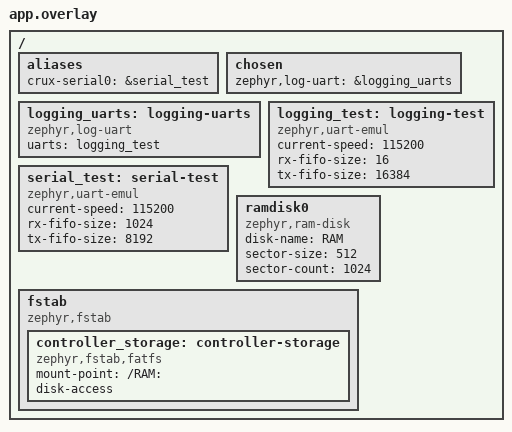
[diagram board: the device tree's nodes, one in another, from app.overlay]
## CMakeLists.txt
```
# SPDX-License-Identifier: Apache-2.0

# The held-application scenario of the controller framework on native_sim: the fixture application
# of ../fixture in the production watchdog configuration with no watchdog (criterion 19). This file
# names no source or include directory of the framework.

cmake_minimum_required(VERSION 3.20.0)
find_package(Zephyr REQUIRED HINTS $ENV{ZEPHYR_BASE})
project(controller_framework_application_held_native_sim LANGUAGES C)

if(NOT CONFIG_BOARD_NATIVE_SIM OR NOT CONFIG_FAKE_ENTROPY_NATIVE_SIM)
    message(FATAL_ERROR "This scenario is restricted to native_sim: its entropy source is a test source")
endif()
if(NOT CONFIG_CRUX_CONTROLLER_FRAMEWORK_SUPERVISION OR NOT CONFIG_CRUX_CONTROLLER_FRAMEWORK_MANAGEMENT
   OR CONFIG_CRUX_CONTROLLER_START_WITHOUT_WATCHDOG OR CONFIG_CRUX_CONTROLLER_FRAMEWORK_FAULT_INJECTION
   OR CONFIG_CRUX_SYSTEM_NATIVE_SIM_WATCHDOG OR CONFIG_TASK_WDT_HW_FALLBACK)
    message(FATAL_ERROR "The held-application scenario needs the production watchdog configuration "
                        "with no watchdog")
endif()

target_sources(app PRIVATE src/test_application_held.c ../fixture/fixture.c ../common/scenario.c)
target_include_directories(app PRIVATE ../common ../fixture)
target_link_libraries(app PRIVATE controller::framework crux::file crux::configuration crux::logging)
controller_framework_image()
```

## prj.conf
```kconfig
# The held-application scenario of the controller framework on native_sim (criterion 19, application
# part, delivery stage 3): the configuration of the base scenario (tests/framework/base/prj.conf), in
# its production watchdog configuration (no task watchdog hardware fallback, no start without a
# watchdog, no fault injection) with no watchdog behind the alias crux-watchdog0, and the fixture
# application of ../fixture. The watchdog is not armed, so the controller is degraded and the
# application is held (decision D14). The program of src/test_application_held.c prints what Twister's console harness
# matches (testcase.yaml); it uses no ztest.
CONFIG_CRUX_CONTROLLER_FRAMEWORK=y
CONFIG_SNTP=y
CONFIG_CRUX_CONTROLLER_TIME_SERVER="127.0.0.1"

# Health supervision as in the base image (app/conf/base.conf), in its production watchdog
# configuration (criterion 19): no task watchdog hardware fallback, no start without a watchdog, no
# fault injection. native_sim has no watchdog behind the alias crux-watchdog0 here, so the watchdog
# is not armed and the controller is degraded. There is no retained region either, so the boot
# counter lives in RAM. The stable period is longer than the scenario, so the counter is not cleared.
CONFIG_TASK_WDT=y
CONFIG_TASK_WDT_HW_FALLBACK=n
CONFIG_CRUX_REBOOT=y
CONFIG_CRUX_CONTROLLER_STABLE_PERIOD_S=3600

CONFIG_CRUX_SERIAL=y
CONFIG_CRUX_CLI=y
CONFIG_CRUX_CLI_CONSOLE=y
CONFIG_CRUX_CLI_CONSOLE_PRIORITY=11
CONFIG_UART_INTERRUPT_DRIVEN=y
CONFIG_UART_USE_RUNTIME_CONFIGURE=y

CONFIG_STD_C17=y
CONFIG_EMUL=y
CONFIG_UART_EMUL=y
CONFIG_IRQ_OFFLOAD=y
# The web adapter refuses the external libc of native_sim; the management scenario runs on picolibc.
CONFIG_PICOLIBC=y
# One thread of the test runs the start sequence (key generation, signing, the format of the RAM
# disk) and the TLS client. Not measured.
CONFIG_MAIN_STACK_SIZE=32768
CONFIG_HEAP_MEM_POOL_SIZE=32768

# The Mbed TLS profile of app/conf/management.conf, as a copy: this scenario has no Kconfig of the product,
# as in the management scenario. The heap is larger than the product's 120,000 bytes,
# because the TLS client of the test runs in the same process and takes up to one more connection
# and its own handshake. The product declares 120,000 bytes for three server connections of 34,912
# bytes, a handshake of 3,576 bytes and the other PSA users, and 180,000 leaves about 25,000 bytes
# over the worst concurrent case that this process can reach. A paper figure, not measured.
CONFIG_MBEDTLS=y
CONFIG_MBEDTLS_PSA_CRYPTO_C=y
CONFIG_PSA_CRYPTO_PROVIDER_MBEDTLS=y
CONFIG_MBEDTLS_ENABLE_HEAP=y
CONFIG_MBEDTLS_HEAP_SIZE=180000
CONFIG_MBEDTLS_SSL_IN_CONTENT_LEN=16384
CONFIG_MBEDTLS_SSL_OUT_CONTENT_LEN=16384
CONFIG_MBEDTLS_SSL_PROTO_TLS1_2=y
CONFIG_MBEDTLS_SSL_PROTO_TLS1_3=y
CONFIG_MBEDTLS_SSL_TLS1_3_KEY_EXCHANGE_MODE_EPHEMERAL_ENABLED=y
CONFIG_MBEDTLS_KEY_EXCHANGE_ECDHE_ECDSA_ENABLED=y
CONFIG_MBEDTLS_CIPHERSUITE_TLS_ECDHE_ECDSA_WITH_AES_128_GCM_SHA256=y
CONFIG_MBEDTLS_CIPHERSUITE_TLS1_3_AES_128_GCM_SHA256=y
CONFIG_PSA_WANT_ALG_SHA_256=y
CONFIG_PSA_WANT_ECC_SECP_R1_256=y
CONFIG_PSA_WANT_ALG_ECDSA=y
CONFIG_PSA_WANT_ALG_ECDH=y
CONFIG_PSA_WANT_ALG_GCM=y
CONFIG_PSA_WANT_KEY_TYPE_AES=y
CONFIG_PSA_WANT_ALG_HMAC=y
CONFIG_PSA_WANT_KEY_TYPE_HMAC=y
CONFIG_PSA_WANT_ALG_HKDF=y
CONFIG_PSA_WANT_ALG_PBKDF2_HMAC=y
CONFIG_PSA_WANT_ALG_TLS12_PRF=y
CONFIG_PSA_WANT_KEY_TYPE_ECC_PUBLIC_KEY=y
CONFIG_PSA_WANT_KEY_TYPE_ECC_KEY_PAIR_IMPORT=y
CONFIG_PSA_WANT_KEY_TYPE_ECC_KEY_PAIR_EXPORT=y
CONFIG_PSA_WANT_KEY_TYPE_ECC_KEY_PAIR_GENERATE=y
CONFIG_PSA_WANT_KEY_TYPE_ECC_KEY_PAIR_DERIVE=y
CONFIG_MBEDTLS_PK_WRITE_C=y
CONFIG_CRUX_PSA_THREADING=y

# The Crux services, as in app/conf/management.conf. The module selects Thread, Sync and Time for them.
CONFIG_CRUX_ACCESS=y
CONFIG_CRUX_CONFIG_SERVICE=y
CONFIG_CRUX_MGMT_STATUS=y
CONFIG_CRUX_TLS_CERTIFICATE=y
CONFIG_CRUX_WEB=y
CONFIG_CRUX_WEB_SESSION=y
CONFIG_CRUX_WEB_MANAGEMENT=y
CONFIG_CRUX_SYSTEM=y
CONFIG_CRUX_NETIF=y
CONFIG_WATCHDOG=y
CONFIG_HWINFO=y
CONFIG_REBOOT=y

# The listener binds the loopback address, and the TLS client of the test is in the same process. The
# listener opens on Zephyr's own thread, so the client retries its connect.
CONFIG_CRUX_WEB_PORT=443
CONFIG_CRUX_WEB_BIND_ADDRESS="127.0.0.1"
CONFIG_CRUX_WEB_BACKLOG=4
CONFIG_HTTP_SERVER_MAX_CLIENTS=3
CONFIG_HTTP_SERVER_STACK_SIZE=16384
CONFIG_CRUX_WEB_SESSION_WORKER_PRIORITY=11
CONFIG_CRUX_WEB_MANAGEMENT_WORKER_PRIORITY=11
CONFIG_CRUX_SECURITY_EVENT_DRAIN_PRIORITY=11

# The simulator's fake entropy source: test-only, so nothing made here is a secret.
CONFIG_ENTROPY_GENERATOR=y

# Crux File on a RAM disk with the simulator provider, and the formatting service that the zone
# uses when the blank disk does not mount.
CONFIG_FILE_SYSTEM=y
CONFIG_FILE_SYSTEM_MKFS=y
CONFIG_FAT_FILESYSTEM_ELM=y
CONFIG_FS_FATFS_LFN=y
CONFIG_FS_FATFS_LFN_MODE_STACK=y
CONFIG_FS_FATFS_MAX_LFN=127
CONFIG_FS_FATFS_MOUNT_MKFS=n
CONFIG_FS_FATFS_REENTRANT=y
CONFIG_FS_FATFS_NUM_FILES=6
CONFIG_DISK_DRIVERS=y
CONFIG_DISK_DRIVER_RAM=y
CONFIG_CRUX_FILE_FATFS_SIMULATOR=y

# The network: Zephyr's loopback interface, TCP and the TLS socket layer, with no host network.
CONFIG_NETWORKING=y
CONFIG_NET_IPV4=y
CONFIG_NET_IPV6=n
CONFIG_NET_TCP=y
CONFIG_NET_UDP=y
CONFIG_NET_SOCKETS=y
CONFIG_NET_DRIVERS=y
CONFIG_NET_LOOPBACK=y
CONFIG_NET_SOCKETS_SOCKOPT_TLS=y
CONFIG_TLS_CREDENTIALS=y
CONFIG_TLS_MAX_CREDENTIALS_NUMBER=4
CONFIG_NET_SOCKETS_TLS_MAX_CONTEXTS=6
CONFIG_ZVFS_OPEN_MAX=48
CONFIG_ZVFS_POLL_MAX=24
CONFIG_ZVFS_EVENTFD=y
CONFIG_NET_MAX_CONTEXTS=32
CONFIG_NET_MAX_CONN=32
CONFIG_NET_PKT_RX_COUNT=64
CONFIG_NET_PKT_TX_COUNT=64
CONFIG_NET_BUF_RX_COUNT=256
CONFIG_NET_BUF_TX_COUNT=256

# Crux Logging writes to an emulated UART, so that the test can read what it wrote.
CONFIG_CRUX_LOGGING=y
CONFIG_SERIAL=y
CONFIG_LOG=y
CONFIG_LOG_MODE_DEFERRED=y
CONFIG_LOG_MODE_OVERFLOW=n
CONFIG_LOG_BLOCK_IN_THREAD=n
CONFIG_LOG_PROCESS_THREAD=y
CONFIG_LOG_PROCESS_THREAD_STACK_SIZE=2048
CONFIG_LOG_PROCESS_THREAD_CUSTOM_PRIORITY=y
CONFIG_LOG_PROCESS_THREAD_PRIORITY=14
CONFIG_LOG_BUFFER_SIZE=8192
CONFIG_LOG_MAX_LEVEL=4
CONFIG_LOG_DEFAULT_LEVEL=0
CONFIG_LOG_RUNTIME_FILTERING=n
CONFIG_LOG_BACKEND_UART=y
CONFIG_LOG_BACKEND_NATIVE_POSIX=n
CONFIG_LOG_BACKEND_UART_ASYNC=n
CONFIG_LOG_PRINTK=n
CONFIG_SHELL_LOG_BACKEND=n
CONFIG_LOG_BACKEND_SHOW_LEVEL=y
CONFIG_LOG_BACKEND_CRLF_NONE=n
CONFIG_THREAD_MONITOR=y
CONFIG_THREAD_NAME=y
# An image with Crux management must not enable the Zephyr shell.
CONFIG_SHELL=n

# --- The application (delivery stage 3) ---------------------------------------------------------
# main() runs the start function, below the supervisor's priority (7).
CONFIG_MAIN_THREAD_PRIORITY=8
# A runtime dependency other than the default (criterion 27): the serial command line, which is healthy
# here, so the controller stays degraded for the watchdog alone.
CONFIG_CRUX_CONTROLLER_DEPENDENCY_COMMAND_LINE=y
```

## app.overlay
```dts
/* The devicetree of the management scenario (tests/native_sim_mbed/management/app.overlay).
 * Crux Logging writes to an emulated UART here, so that the test can read what it wrote. The RAM
 * disk and the fstab entry are the ones that boards/management.overlay declares for the board, with the
 * same names, because the composition zone looks up the entry controller_storage. The disk is
 * blank at every start: the zone formats it. The Crux serial console owns a second emulated UART
 * through the alias crux-serial0: the test types into its receive side and reads its transmit
 * side. */
/ {
    aliases { crux-serial0 = &serial_test; };
    chosen { zephyr,log-uart = &logging_uarts; };
    logging_uarts: logging-uarts {
        compatible = "zephyr,log-uart";
        uarts = <&logging_test>;
    };
    logging_test: logging-test {
        compatible = "zephyr,uart-emul";
        current-speed = <115200>;
        rx-fifo-size = <16>;
        tx-fifo-size = <16384>;
        status = "okay";
    };
    serial_test: serial-test {
        compatible = "zephyr,uart-emul";
        current-speed = <115200>;
        rx-fifo-size = <1024>;
        /* The status command writes more than 1 KiB at once, and the emulated UART drops the bytes
         * that do not fit (uart_emul_poll_out in Zephyr's drivers/serial/uart_emul.c). */
        tx-fifo-size = <8192>;
        status = "okay";
    };

    ramdisk0 {
        compatible = "zephyr,ram-disk";
        disk-name = "RAM";
        sector-size = <512>;
        sector-count = <1024>;
    };

    fstab {
        compatible = "zephyr,fstab";
        controller_storage: controller-storage {
            compatible = "zephyr,fstab,fatfs";
            mount-point = "/RAM:";
            disk-access;
        };
    };
};
```

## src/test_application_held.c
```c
/* SPDX-License-Identifier: Apache-2.0 */

/* The held-application scenario (criterion 19, application part): in the production watchdog
 * configuration, with no watchdog behind the alias crux-watchdog0, the framework initialises the
 * fixture application and holds it in step 12 (decision D14): start is not called, and the
 * controller is degraded. */

#include <stdbool.h>
#include <stdio.h>

#include <controller/framework.h>
#include <zephyr/kernel.h>

#include "fixture.h"
#include "scenario.h"

#define WAIT_STEP_MS 100
#define WAIT_STEPS 100

int main(void)
{
    scenario_forward_log();
    scenario_say("held scenario start");
    if (controller_framework_start(fixture_descriptor(FIXTURE_NORMAL)) != CONTROLLER_FRAMEWORK_OK) {
        scenario_say("held scenario FAILED: the start function");
        return 0;
    }
    bool degraded = false;

    for (int step = 0; step < WAIT_STEPS && !degraded; step++) {
        degraded = fixture_controller_state() == CONTROLLER_FRAMEWORK_STATE_DEGRADED;
        k_msleep(WAIT_STEP_MS);
    }
    k_msleep(1000);
    if (degraded && fixture_inits() == 1u && fixture_starts() == 0u) {
        scenario_say("held scenario: initialised, not started, controller degraded");
    } else {
        scenario_say("held scenario FAILED: the hold");
    }
    for (;;) {
        k_sleep(K_FOREVER);
    }
    return 0;
}
```
